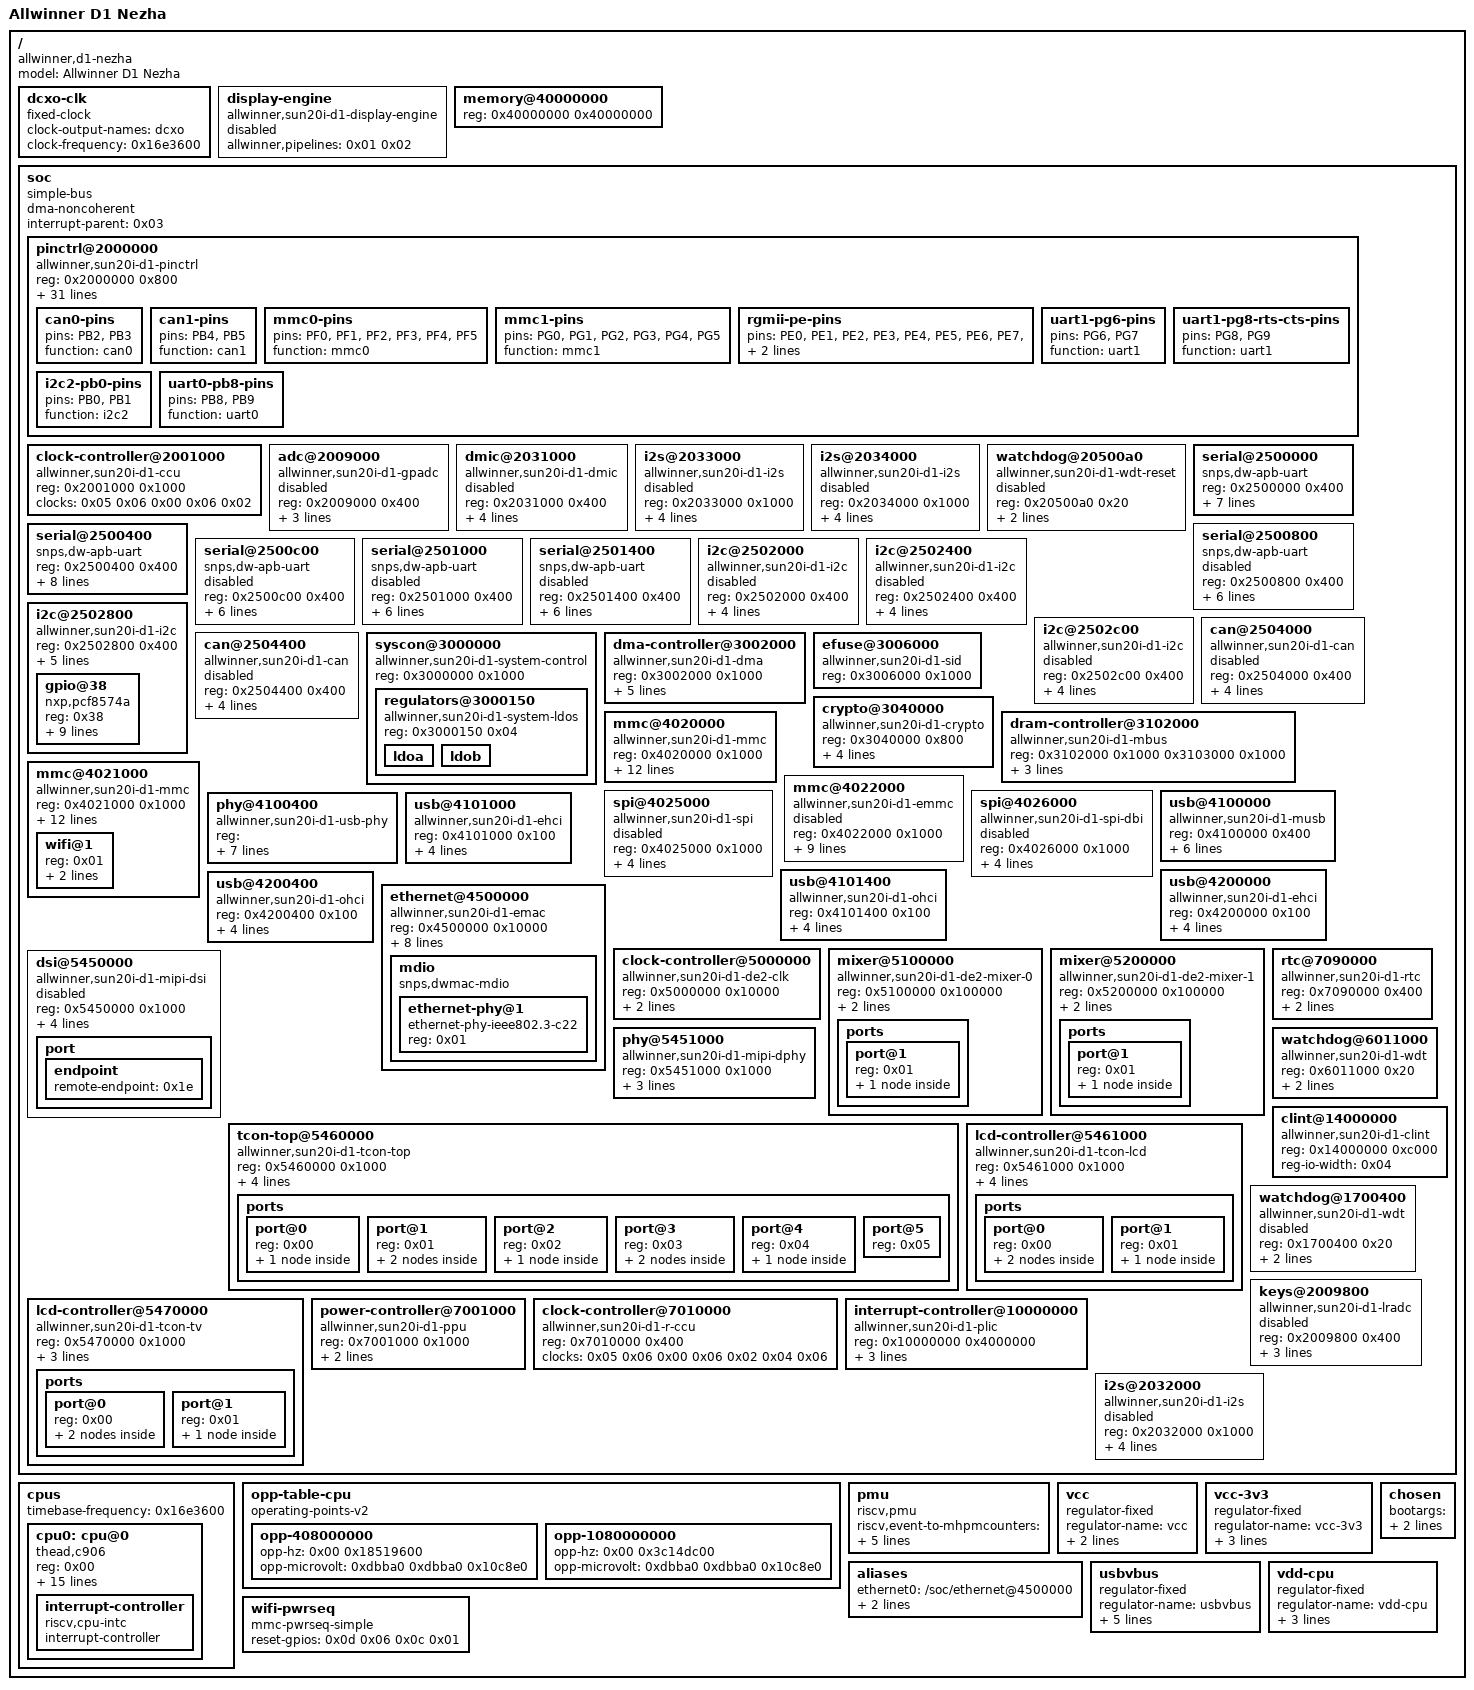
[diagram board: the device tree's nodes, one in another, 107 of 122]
/dts-v1/;

/ {
	#address-cells = <0x01>;
	#size-cells = <0x01>;
	model = "Allwinner D1 Nezha";
	compatible = "allwinner,d1-nezha", "allwinner,sun20i-d1";

	dcxo-clk {
		compatible = "fixed-clock";
		clock-output-names = "dcxo";
		#clock-cells = <0x00>;
		clock-frequency = <0x16e3600>;
		phandle = <0x05>;
	};

	display-engine {
		compatible = "allwinner,sun20i-d1-display-engine";
		allwinner,pipelines = <0x01 0x02>;
		status = "disabled";
	};

	memory@40000000 {
		device_type = "memory";
		reg = <0x40000000 0x40000000>;
	};

	soc {
		compatible = "simple-bus";
		ranges;
		dma-noncoherent;
		#address-cells = <0x01>;
		#size-cells = <0x01>;
		interrupt-parent = <0x03>;

		pinctrl@2000000 {
			compatible = "allwinner,sun20i-d1-pinctrl";
			reg = <0x2000000 0x800>;
			interrupts = <0x55 0x04 0x57 0x04 0x59 0x04 0x5b 0x04 0x5d 0x04 0x5f 0x04>;
			clocks = <0x04 0x18 0x05 0x06 0x00>;
			clock-names = "apb", "hosc", "losc";
			gpio-controller;
			interrupt-controller;
			#gpio-cells = <0x03>;
			#interrupt-cells = <0x03>;
			vcc-pb-supply = <0x07>;
			vcc-pc-supply = <0x07>;
			vcc-pd-supply = <0x07>;
			vcc-pe-supply = <0x07>;
			vcc-pf-supply = <0x07>;
			vcc-pg-supply = <0x07>;
			gpio-line-names = "", "", "", "", "", "", "", "", "", "", "", "", "", "", "", "", "", "", "", "", "", "", "", "", "", "", "", "", "", "", "", "", "pin5 [gpio2/twi2-sck]", "pin3 [gpio1/twi2-sda]", "", "pin38 [gpio24/i2s2-din]", "pin40 [gpio25/i2s2-dout]", "pin12 [gpio7/i2s-clk]", "pin35 [gpio22/i2s2-lrck]", "", "pin8 [gpio4/uart0-txd]", "pin10 [gpio5/uart0-rxd]", "", "", "pin15 [gpio9]", "", "", "", "", "", "", "", "", "", "", "", "", "", "", "", "", "", "", "", "", "", "pin31 [gpio21]", "", "", "", "", "", "", "", "", "", "", "", "", "", "", "", "", "", "", "", "", "", "", "", "", "", "", "", "", "", "", "", "", "", "", "", "", "", "", "", "", "pin24 [gpio16/spi1-ce0]", "pin23 [gpio15/spi1-clk]", "pin19 [gpio12/spi1-mosi]", "pin21 [gpio13/spi1-miso]", "pin27 [gpio18/spi1-hold]", "pin29 [gpio20/spi1-wp]", "", "", "", "", "", "", "pin7 [gpio3/pwm]";
			phandle = <0x0d>;

			can0-pins {
				pins = "PB2", "PB3";
				function = "can0";
				phandle = <0x0e>;
			};

			can1-pins {
				pins = "PB4", "PB5";
				function = "can1";
				phandle = <0x0f>;
			};

			mmc0-pins {
				pins = "PF0", "PF1", "PF2", "PF3", "PF4", "PF5";
				function = "mmc0";
				phandle = <0x10>;
			};

			mmc1-pins {
				pins = "PG0", "PG1", "PG2", "PG3", "PG4", "PG5";
				function = "mmc1";
				phandle = <0x12>;
			};

			rgmii-pe-pins {
				pins = "PE0", "PE1", "PE2", "PE3", "PE4", "PE5", "PE6", "PE7", "PE8", "PE9", "PE11", "PE12", "PE13", "PE14", "PE15";
				function = "emac";
				phandle = <0x17>;
			};

			uart1-pg6-pins {
				pins = "PG6", "PG7";
				function = "uart1";
				phandle = <0x0a>;
			};

			uart1-pg8-rts-cts-pins {
				pins = "PG8", "PG9";
				function = "uart1";
				phandle = <0x0b>;
			};

			i2c2-pb0-pins {
				pins = "PB0", "PB1";
				function = "i2c2";
				phandle = <0x0c>;
			};

			uart0-pb8-pins {
				pins = "PB8", "PB9";
				function = "uart0";
				phandle = <0x09>;
			};
		};

		clock-controller@2001000 {
			compatible = "allwinner,sun20i-d1-ccu";
			reg = <0x2001000 0x1000>;
			clocks = <0x05 0x06 0x00 0x06 0x02>;
			clock-names = "hosc", "losc", "iosc";
			#clock-cells = <0x01>;
			#reset-cells = <0x01>;
			phandle = <0x04>;
		};

		adc@2009000 {
			compatible = "allwinner,sun20i-d1-gpadc";
			reg = <0x2009000 0x400>;
			clocks = <0x04 0x50>;
			resets = <0x04 0x20>;
			interrupts = <0x49 0x04>;
			status = "disabled";
			#io-channel-cells = <0x01>;
		};

		dmic@2031000 {
			compatible = "allwinner,sun20i-d1-dmic", "allwinner,sun50i-h6-dmic";
			reg = <0x2031000 0x400>;
			interrupts = <0x28 0x04>;
			clocks = <0x04 0x5d 0x04 0x5c>;
			clock-names = "bus", "mod";
			resets = <0x04 0x26>;
			dmas = <0x08 0x08>;
			dma-names = "rx";
			status = "disabled";
			#sound-dai-cells = <0x00>;
		};

		i2s@2033000 {
			compatible = "allwinner,sun20i-d1-i2s", "allwinner,sun50i-r329-i2s";
			reg = <0x2033000 0x1000>;
			interrupts = <0x2b 0x04>;
			clocks = <0x04 0x57 0x04 0x53>;
			clock-names = "apb", "mod";
			resets = <0x04 0x23>;
			dmas = <0x08 0x04 0x08 0x04>;
			dma-names = "rx", "tx";
			status = "disabled";
			#sound-dai-cells = <0x00>;
		};

		i2s@2034000 {
			compatible = "allwinner,sun20i-d1-i2s", "allwinner,sun50i-r329-i2s";
			reg = <0x2034000 0x1000>;
			interrupts = <0x2c 0x04>;
			clocks = <0x04 0x58 0x04 0x54>;
			clock-names = "apb", "mod";
			resets = <0x04 0x24>;
			dmas = <0x08 0x05 0x08 0x05>;
			dma-names = "rx", "tx";
			status = "disabled";
			#sound-dai-cells = <0x00>;
		};

		// timer@2050000 {
		// 	compatible = "allwinner,sun20i-d1-timer", "allwinner,sun8i-a23-timer";
		// 	reg = <0x2050000 0xa0>;
		// 	interrupts = <0x4b 0x04 0x4c 0x04>;
		// 	clocks = <0x05>;
		// };

		watchdog@20500a0 {
			compatible = "allwinner,sun20i-d1-wdt-reset", "allwinner,sun20i-d1-wdt";
			reg = <0x20500a0 0x20>;
			interrupts = <0x4f 0x04>;
			clocks = <0x05 0x06 0x00>;
			clock-names = "hosc", "losc";
			status = "reserved";
		};

		serial@2500000 {
			compatible = "snps,dw-apb-uart";
			reg = <0x2500000 0x400>;
			reg-io-width = <0x04>;
			reg-shift = <0x02>;
			interrupts = <0x12 0x04>;
			clocks = <0x04 0x3e>;
			resets = <0x04 0x12>;
			dmas = <0x08 0x0e 0x08 0x0e>;
			dma-names = "tx", "rx";
			status = "okay";
			pinctrl-0 = <0x09>;
			pinctrl-names = "default";
		};

		serial@2500400 {
			compatible = "snps,dw-apb-uart";
			reg = <0x2500400 0x400>;
			reg-io-width = <0x04>;
			reg-shift = <0x02>;
			interrupts = <0x13 0x04>;
			clocks = <0x04 0x3f>;
			resets = <0x04 0x13>;
			dmas = <0x08 0x0f 0x08 0x0f>;
			dma-names = "tx", "rx";
			status = "okay";
			uart-has-rtscts;
			pinctrl-0 = <0x0a 0x0b>;
			pinctrl-names = "default";
		};

		serial@2500800 {
			compatible = "snps,dw-apb-uart";
			reg = <0x2500800 0x400>;
			reg-io-width = <0x04>;
			reg-shift = <0x02>;
			interrupts = <0x14 0x04>;
			clocks = <0x04 0x40>;
			resets = <0x04 0x14>;
			dmas = <0x08 0x10 0x08 0x10>;
			dma-names = "tx", "rx";
			status = "disabled";
		};

		serial@2500c00 {
			compatible = "snps,dw-apb-uart";
			reg = <0x2500c00 0x400>;
			reg-io-width = <0x04>;
			reg-shift = <0x02>;
			interrupts = <0x15 0x04>;
			clocks = <0x04 0x41>;
			resets = <0x04 0x15>;
			dmas = <0x08 0x11 0x08 0x11>;
			dma-names = "tx", "rx";
			status = "disabled";
		};

		serial@2501000 {
			compatible = "snps,dw-apb-uart";
			reg = <0x2501000 0x400>;
			reg-io-width = <0x04>;
			reg-shift = <0x02>;
			interrupts = <0x16 0x04>;
			clocks = <0x04 0x42>;
			resets = <0x04 0x16>;
			dmas = <0x08 0x12 0x08 0x12>;
			dma-names = "tx", "rx";
			status = "disabled";
		};

		serial@2501400 {
			compatible = "snps,dw-apb-uart";
			reg = <0x2501400 0x400>;
			reg-io-width = <0x04>;
			reg-shift = <0x02>;
			interrupts = <0x17 0x04>;
			clocks = <0x04 0x43>;
			resets = <0x04 0x17>;
			dmas = <0x08 0x13 0x08 0x13>;
			dma-names = "tx", "rx";
			status = "disabled";
		};

		i2c@2502000 {
			compatible = "allwinner,sun20i-d1-i2c", "allwinner,sun8i-v536-i2c", "allwinner,sun6i-a31-i2c";
			reg = <0x2502000 0x400>;
			interrupts = <0x19 0x04>;
			clocks = <0x04 0x44>;
			resets = <0x04 0x18>;
			dmas = <0x08 0x2b 0x08 0x2b>;
			dma-names = "rx", "tx";
			status = "disabled";
			#address-cells = <0x01>;
			#size-cells = <0x00>;
		};

		i2c@2502400 {
			compatible = "allwinner,sun20i-d1-i2c", "allwinner,sun8i-v536-i2c", "allwinner,sun6i-a31-i2c";
			reg = <0x2502400 0x400>;
			interrupts = <0x1a 0x04>;
			clocks = <0x04 0x45>;
			resets = <0x04 0x19>;
			dmas = <0x08 0x2c 0x08 0x2c>;
			dma-names = "rx", "tx";
			status = "disabled";
			#address-cells = <0x01>;
			#size-cells = <0x00>;
		};

		i2c@2502800 {
			compatible = "allwinner,sun20i-d1-i2c", "allwinner,sun8i-v536-i2c", "allwinner,sun6i-a31-i2c";
			reg = <0x2502800 0x400>;
			interrupts = <0x1b 0x04>;
			clocks = <0x04 0x46>;
			resets = <0x04 0x1a>;
			dmas = <0x08 0x2d 0x08 0x2d>;
			dma-names = "rx", "tx";
			status = "okay";
			#address-cells = <0x01>;
			#size-cells = <0x00>;
			pinctrl-0 = <0x0c>;
			pinctrl-names = "default";

			gpio@38 {
				compatible = "nxp,pcf8574a";
				reg = <0x38>;
				interrupt-parent = <0x0d>;
				interrupts = <0x01 0x02 0x08>;
				interrupt-controller;
				gpio-controller;
				#gpio-cells = <0x02>;
				#interrupt-cells = <0x02>;
				gpio-line-names = "pin13 [gpio8]", "pin16 [gpio10]", "pin18 [gpio11]", "pin26 [gpio17]", "pin22 [gpio14]", "pin28 [gpio19]", "pin37 [gpio23]", "pin11 [gpio6]";
			};
		};

		i2c@2502c00 {
			compatible = "allwinner,sun20i-d1-i2c", "allwinner,sun8i-v536-i2c", "allwinner,sun6i-a31-i2c";
			reg = <0x2502c00 0x400>;
			interrupts = <0x1c 0x04>;
			clocks = <0x04 0x47>;
			resets = <0x04 0x1b>;
			dmas = <0x08 0x2e 0x08 0x2e>;
			dma-names = "rx", "tx";
			status = "disabled";
			#address-cells = <0x01>;
			#size-cells = <0x00>;
		};

		can@2504000 {
			compatible = "allwinner,sun20i-d1-can";
			reg = <0x2504000 0x400>;
			interrupts = <0x25 0x04>;
			clocks = <0x04 0x91>;
			resets = <0x04 0x42>;
			pinctrl-names = "default";
			pinctrl-0 = <0x0e>;
			status = "disabled";
		};

		can@2504400 {
			compatible = "allwinner,sun20i-d1-can";
			reg = <0x2504400 0x400>;
			interrupts = <0x26 0x04>;
			clocks = <0x04 0x92>;
			resets = <0x04 0x43>;
			pinctrl-names = "default";
			pinctrl-0 = <0x0f>;
			status = "disabled";
		};

		syscon@3000000 {
			compatible = "allwinner,sun20i-d1-system-control";
			reg = <0x3000000 0x1000>;
			ranges;
			#address-cells = <0x01>;
			#size-cells = <0x01>;
			phandle = <0x16>;

			regulators@3000150 {
				compatible = "allwinner,sun20i-d1-system-ldos";
				reg = <0x3000150 0x04>;

				ldoa {
				};

				ldob {
				};
			};
		};

		dma-controller@3002000 {
			compatible = "allwinner,sun20i-d1-dma";
			reg = <0x3002000 0x1000>;
			interrupts = <0x42 0x04>;
			clocks = <0x04 0x25 0x04 0x30>;
			clock-names = "bus", "mbus";
			resets = <0x04 0x06>;
			dma-channels = <0x10>;
			dma-requests = <0x30>;
			#dma-cells = <0x01>;
			phandle = <0x08>;
		};

		efuse@3006000 {
			compatible = "allwinner,sun20i-d1-sid";
			reg = <0x3006000 0x1000>;
			#address-cells = <0x01>;
			#size-cells = <0x01>;
		};

		crypto@3040000 {
			compatible = "allwinner,sun20i-d1-crypto";
			reg = <0x3040000 0x800>;
			interrupts = <0x44 0x04>;
			clocks = <0x04 0x22 0x04 0x21 0x04 0x32 0x06 0x02>;
			clock-names = "bus", "mod", "ram", "trng";
			resets = <0x04 0x04>;
		};

		dram-controller@3102000 {
			compatible = "allwinner,sun20i-d1-mbus";
			reg = <0x3102000 0x1000 0x3103000 0x1000>;
			reg-names = "mbus", "dram";
			interrupts = <0x3b 0x04>;
			clocks = <0x04 0x1a 0x04 0x2f 0x04 0x37>;
			clock-names = "mbus", "dram", "bus";
			dma-ranges = <0x00 0x40000000 0x80000000>;
			#address-cells = <0x01>;
			#size-cells = <0x01>;
			#interconnect-cells = <0x01>;
		};

		mmc@4020000 {
			compatible = "allwinner,sun20i-d1-mmc";
			reg = <0x4020000 0x1000>;
			interrupts = <0x38 0x04>;
			clocks = <0x04 0x3b 0x04 0x38>;
			clock-names = "ahb", "mmc";
			resets = <0x04 0x0f>;
			reset-names = "ahb";
			cap-sd-highspeed;
			max-frequency = <0x8f0d180>;
			no-mmc;
			status = "okay";
			#address-cells = <0x01>;
			#size-cells = <0x00>;
			bus-width = <0x04>;
			cd-gpios = <0x0d 0x05 0x06 0x00>;
			disable-wp;
			vmmc-supply = <0x07>;
			vqmmc-supply = <0x07>;
			pinctrl-0 = <0x10>;
			pinctrl-names = "default";
		};

		mmc@4021000 {
			compatible = "allwinner,sun20i-d1-mmc";
			reg = <0x4021000 0x1000>;
			interrupts = <0x39 0x04>;
			clocks = <0x04 0x3c 0x04 0x39>;
			clock-names = "ahb", "mmc";
			resets = <0x04 0x10>;
			reset-names = "ahb";
			cap-sd-highspeed;
			max-frequency = <0x8f0d180>;
			no-mmc;
			status = "okay";
			#address-cells = <0x01>;
			#size-cells = <0x00>;
			bus-width = <0x04>;
			mmc-pwrseq = <0x11>;
			non-removable;
			vmmc-supply = <0x07>;
			vqmmc-supply = <0x07>;
			pinctrl-0 = <0x12>;
			pinctrl-names = "default";

			wifi@1 {
				reg = <0x01>;
				interrupt-parent = <0x0d>;
				interrupts = <0x06 0x0a 0x08>;
				interrupt-names = "host-wake";
			};
		};

		mmc@4022000 {
			compatible = "allwinner,sun20i-d1-emmc", "allwinner,sun50i-a100-emmc";
			reg = <0x4022000 0x1000>;
			interrupts = <0x3a 0x04>;
			clocks = <0x04 0x3d 0x04 0x3a>;
			clock-names = "ahb", "mmc";
			resets = <0x04 0x11>;
			reset-names = "ahb";
			cap-mmc-highspeed;
			max-frequency = <0x8f0d180>;
			mmc-ddr-1_8v;
			mmc-ddr-3_3v;
			no-sd;
			no-sdio;
			status = "disabled";
			#address-cells = <0x01>;
			#size-cells = <0x00>;
		};

		spi@4025000 {
			compatible = "allwinner,sun20i-d1-spi", "allwinner,sun50i-r329-spi";
			reg = <0x4025000 0x1000>;
			interrupts = <0x1f 0x04>;
			clocks = <0x04 0x4a 0x04 0x48>;
			clock-names = "ahb", "mod";
			dmas = <0x08 0x16 0x08 0x16>;
			dma-names = "rx", "tx";
			resets = <0x04 0x1c>;
			status = "disabled";
			#address-cells = <0x01>;
			#size-cells = <0x00>;
		};

		spi@4026000 {
			compatible = "allwinner,sun20i-d1-spi-dbi", "allwinner,sun50i-r329-spi-dbi", "allwinner,sun50i-r329-spi";
			reg = <0x4026000 0x1000>;
			interrupts = <0x20 0x04>;
			clocks = <0x04 0x4b 0x04 0x49>;
			clock-names = "ahb", "mod";
			dmas = <0x08 0x17 0x08 0x17>;
			dma-names = "rx", "tx";
			resets = <0x04 0x1d>;
			status = "disabled";
			#address-cells = <0x01>;
			#size-cells = <0x00>;
		};

		usb@4100000 {
			compatible = "allwinner,sun20i-d1-musb", "allwinner,sun8i-a33-musb";
			reg = <0x4100000 0x400>;
			interrupts = <0x2d 0x04>;
			interrupt-names = "mc";
			clocks = <0x04 0x67>;
			resets = <0x04 0x2e>;
			extcon = <0x13 0x00>;
			phys = <0x13 0x00>;
			phy-names = "usb";
			status = "okay";
			dr_mode = "otg";
		};

		phy@4100400 {
			compatible = "allwinner,sun20i-d1-usb-phy";
			reg = <0x4100400 0x100 0x4101800 0x100 0x4200800 0x100>;
			reg-names = "phy_ctrl", "pmu0", "pmu1";
			clocks = <0x05 0x05>;
			clock-names = "usb0_phy", "usb1_phy";
			resets = <0x04 0x28 0x04 0x29>;
			reset-names = "usb0_reset", "usb1_reset";
			status = "okay";
			#phy-cells = <0x01>;
			usb0_id_det-gpios = <0x0d 0x03 0x15 0x00>;
			usb0_vbus_det-gpios = <0x0d 0x03 0x14 0x00>;
			usb0_vbus-supply = <0x14>;
			usb1_vbus-supply = <0x15>;
			phandle = <0x13>;
		};

		usb@4101000 {
			compatible = "allwinner,sun20i-d1-ehci", "generic-ehci";
			reg = <0x4101000 0x100>;
			interrupts = <0x2e 0x04>;
			clocks = <0x04 0x63 0x04 0x65 0x04 0x61>;
			resets = <0x04 0x2a 0x04 0x2c>;
			phys = <0x13 0x00>;
			phy-names = "usb";
			status = "okay";
		};

		usb@4101400 {
			compatible = "allwinner,sun20i-d1-ohci", "generic-ohci";
			reg = <0x4101400 0x100>;
			interrupts = <0x2f 0x04>;
			clocks = <0x04 0x63 0x04 0x61>;
			resets = <0x04 0x2a>;
			phys = <0x13 0x00>;
			phy-names = "usb";
			status = "okay";
		};

		usb@4200000 {
			compatible = "allwinner,sun20i-d1-ehci", "generic-ehci";
			reg = <0x4200000 0x100>;
			interrupts = <0x31 0x04>;
			clocks = <0x04 0x64 0x04 0x66 0x04 0x62>;
			resets = <0x04 0x2b 0x04 0x2d>;
			phys = <0x13 0x01>;
			phy-names = "usb";
			status = "okay";
		};

		usb@4200400 {
			compatible = "allwinner,sun20i-d1-ohci", "generic-ohci";
			reg = <0x4200400 0x100>;
			interrupts = <0x32 0x04>;
			clocks = <0x04 0x64 0x04 0x62>;
			resets = <0x04 0x2b>;
			phys = <0x13 0x01>;
			phy-names = "usb";
			status = "okay";
		};

		ethernet@4500000 {
			compatible = "allwinner,sun20i-d1-emac", "allwinner,sun50i-a64-emac";
			reg = <0x4500000 0x10000>;
			interrupts = <0x3e 0x04>;
			interrupt-names = "macirq";
			clocks = <0x04 0x4d>;
			clock-names = "stmmaceth";
			resets = <0x04 0x1e>;
			reset-names = "stmmaceth";
			syscon = <0x16>;
			status = "okay";
			pinctrl-0 = <0x17>;
			pinctrl-names = "default";
			phy-handle = <0x18>;
			phy-mode = "rgmii-id";
			phy-supply = <0x07>;

			mdio {
				compatible = "snps,dwmac-mdio";
				#address-cells = <0x01>;
				#size-cells = <0x00>;

				ethernet-phy@1 {
					compatible = "ethernet-phy-ieee802.3-c22";
					reg = <0x01>;
					phandle = <0x18>;
				};
			};
		};

		clock-controller@5000000 {
			compatible = "allwinner,sun20i-d1-de2-clk", "allwinner,sun50i-h5-de2-clk";
			reg = <0x5000000 0x10000>;
			clocks = <0x04 0x1c 0x04 0x1b>;
			clock-names = "bus", "mod";
			resets = <0x04 0x01>;
			#clock-cells = <0x01>;
			#reset-cells = <0x01>;
			phandle = <0x19>;
		};

		mixer@5100000 {
			compatible = "allwinner,sun20i-d1-de2-mixer-0";
			reg = <0x5100000 0x100000>;
			clocks = <0x19 0x00 0x19 0x06>;
			clock-names = "bus", "mod";
			resets = <0x19 0x00>;
			phandle = <0x01>;

			ports {
				#address-cells = <0x01>;
				#size-cells = <0x00>;

				port@1 {
					reg = <0x01>;

					endpoint {
						remote-endpoint = <0x1a>;
						phandle = <0x1f>;
					};
				};
			};
		};

		mixer@5200000 {
			compatible = "allwinner,sun20i-d1-de2-mixer-1";
			reg = <0x5200000 0x100000>;
			clocks = <0x19 0x01 0x19 0x07>;
			clock-names = "bus", "mod";
			resets = <0x19 0x01>;
			phandle = <0x02>;

			ports {
				#address-cells = <0x01>;
				#size-cells = <0x00>;

				port@1 {
					reg = <0x01>;

					endpoint {
						remote-endpoint = <0x1b>;
						phandle = <0x22>;
					};
				};
			};
		};

		dsi@5450000 {
			compatible = "allwinner,sun20i-d1-mipi-dsi", "allwinner,sun50i-a100-mipi-dsi";
			reg = <0x5450000 0x1000>;
			interrupts = <0x6c 0x04>;
			clocks = <0x04 0x6f 0x1c 0x02>;
			clock-names = "bus", "mod";
			resets = <0x04 0x33>;
			phys = <0x1d>;
			phy-names = "dphy";
			status = "disabled";

			port {

				endpoint {
					remote-endpoint = <0x1e>;
					phandle = <0x28>;
				};
			};
		};

		phy@5451000 {
			compatible = "allwinner,sun20i-d1-mipi-dphy", "allwinner,sun50i-a100-mipi-dphy";
			reg = <0x5451000 0x1000>;
			interrupts = <0x6c 0x04>;
			clocks = <0x04 0x6f 0x04 0x6e>;
			clock-names = "bus", "mod";
			resets = <0x04 0x33>;
			#phy-cells = <0x00>;
			phandle = <0x1d>;
		};

		tcon-top@5460000 {
			compatible = "allwinner,sun20i-d1-tcon-top";
			reg = <0x5460000 0x1000>;
			clocks = <0x04 0x69 0x04 0x72 0x04 0x74 0x04 0x70>;
			clock-names = "bus", "tcon-tv0", "tve0", "dsi";
			clock-output-names = "tcon-top-tv0", "tcon-top-dsi";
			resets = <0x04 0x30>;
			#clock-cells = <0x01>;
			phandle = <0x1c>;

			ports {
				#address-cells = <0x01>;
				#size-cells = <0x00>;

				port@0 {
					reg = <0x00>;

					endpoint {
						remote-endpoint = <0x1f>;
						phandle = <0x1a>;
					};
				};

				port@1 {
					reg = <0x01>;
					#address-cells = <0x01>;
					#size-cells = <0x00>;

					endpoint@0 {
						reg = <0x00>;
						remote-endpoint = <0x20>;
						phandle = <0x26>;
					};

					endpoint@2 {
						reg = <0x02>;
						remote-endpoint = <0x21>;
						phandle = <0x29>;
					};
				};

				port@2 {
					reg = <0x02>;
					#address-cells = <0x01>;
					#size-cells = <0x00>;

					endpoint@1 {
						reg = <0x01>;
						remote-endpoint = <0x22>;
						phandle = <0x1b>;
					};
				};

				port@3 {
					reg = <0x03>;
					#address-cells = <0x01>;
					#size-cells = <0x00>;

					endpoint@0 {
						reg = <0x00>;
						remote-endpoint = <0x23>;
						phandle = <0x27>;
					};

					endpoint@2 {
						reg = <0x02>;
						remote-endpoint = <0x24>;
						phandle = <0x2a>;
					};
				};

				port@4 {
					reg = <0x04>;

					endpoint {
						remote-endpoint = <0x25>;
						phandle = <0x2b>;
					};
				};

				port@5 {
					reg = <0x05>;
				};
			};
		};

		lcd-controller@5461000 {
			compatible = "allwinner,sun20i-d1-tcon-lcd";
			reg = <0x5461000 0x1000>;
			interrupts = <0x6a 0x04>;
			clocks = <0x04 0x71 0x04 0x70>;
			clock-names = "ahb", "tcon-ch0";
			clock-output-names = "tcon-pixel-clock";
			resets = <0x04 0x34 0x04 0x36>;
			reset-names = "lcd", "lvds";
			#clock-cells = <0x00>;

			ports {
				#address-cells = <0x01>;
				#size-cells = <0x00>;

				port@0 {
					reg = <0x00>;
					#address-cells = <0x01>;
					#size-cells = <0x00>;

					endpoint@0 {
						reg = <0x00>;
						remote-endpoint = <0x26>;
						phandle = <0x20>;
					};

					endpoint@1 {
						reg = <0x01>;
						remote-endpoint = <0x27>;
						phandle = <0x23>;
					};
				};

				port@1 {
					reg = <0x01>;
					#address-cells = <0x01>;
					#size-cells = <0x00>;

					endpoint@1 {
						reg = <0x01>;
						remote-endpoint = <0x28>;
						phandle = <0x1e>;
					};
				};
			};
		};

		lcd-controller@5470000 {
			compatible = "allwinner,sun20i-d1-tcon-tv";
			reg = <0x5470000 0x1000>;
			interrupts = <0x6b 0x04>;
			clocks = <0x04 0x73 0x1c 0x00>;
			clock-names = "ahb", "tcon-ch1";
			resets = <0x04 0x35>;
			reset-names = "lcd";

			ports {
				#address-cells = <0x01>;
				#size-cells = <0x00>;

				port@0 {
					reg = <0x00>;
					#address-cells = <0x01>;
					#size-cells = <0x00>;

					endpoint@0 {
						reg = <0x00>;
						remote-endpoint = <0x29>;
						phandle = <0x21>;
					};

					endpoint@1 {
						reg = <0x01>;
						remote-endpoint = <0x2a>;
						phandle = <0x24>;
					};
				};

				port@1 {
					reg = <0x01>;

					endpoint {
						remote-endpoint = <0x2b>;
						phandle = <0x25>;
					};
				};
			};
		};

		power-controller@7001000 {
			compatible = "allwinner,sun20i-d1-ppu";
			reg = <0x7001000 0x1000>;
			clocks = <0x2c 0x04>;
			resets = <0x2c 0x02>;
			#power-domain-cells = <0x01>;
		};

		clock-controller@7010000 {
			compatible = "allwinner,sun20i-d1-r-ccu";
			reg = <0x7010000 0x400>;
			clocks = <0x05 0x06 0x00 0x06 0x02 0x04 0x06>;
			clock-names = "hosc", "losc", "iosc", "pll-periph";
			#clock-cells = <0x01>;
			#reset-cells = <0x01>;
			phandle = <0x2c>;
		};

		rtc@7090000 {
			compatible = "allwinner,sun20i-d1-rtc", "allwinner,sun50i-r329-rtc";
			reg = <0x7090000 0x400>;
			interrupts = <0xa0 0x04>;
			clocks = <0x2c 0x07 0x05 0x2c 0x00>;
			clock-names = "bus", "hosc", "ahb";
			#clock-cells = <0x01>;
			phandle = <0x06>;
		};

		watchdog@6011000 {
			compatible = "allwinner,sun20i-d1-wdt";
			reg = <0x6011000 0x20>;
			interrupts = <0x93 0x04>;
			clocks = <0x05 0x06 0x00>;
			clock-names = "hosc", "losc";
		};

		interrupt-controller@10000000 {
			compatible = "allwinner,sun20i-d1-plic", "thead,c900-plic";
			reg = <0x10000000 0x4000000>;
			interrupts-extended = <0x2d 0x0b 0x2d 0x09>;
			interrupt-controller;
			riscv,ndev = <0xaf>;
			#address-cells = <0x00>;
			#interrupt-cells = <0x02>;
			phandle = <0x03>;
		};

		clint@14000000 {
			compatible = "allwinner,sun20i-d1-clint", "sifive,clint0";
			reg = <0x14000000 0xc000>;
			reg-io-width = <0x04>;
		};

		watchdog@1700400 {
			compatible = "allwinner,sun20i-d1-wdt";
			reg = <0x1700400 0x20>;
			interrupts = <0x8a 0x04>;
			clocks = <0x05 0x06 0x00>;
			clock-names = "hosc", "losc";
			status = "reserved";
		};

		keys@2009800 {
			compatible = "allwinner,sun20i-d1-lradc", "allwinner,sun50i-r329-lradc";
			reg = <0x2009800 0x400>;
			interrupts = <0x4d 0x04>;
			clocks = <0x04 0x68>;
			resets = <0x04 0x2f>;
			status = "disabled";
		};

		i2s@2032000 {
			compatible = "allwinner,sun20i-d1-i2s", "allwinner,sun50i-r329-i2s";
			reg = <0x2032000 0x1000>;
			interrupts = <0x2a 0x04>;
			clocks = <0x04 0x56 0x04 0x52>;
			clock-names = "apb", "mod";
			resets = <0x04 0x22>;
			dmas = <0x08 0x03 0x08 0x03>;
			dma-names = "rx", "tx";
			status = "disabled";
			#sound-dai-cells = <0x00>;
		};
	};

	cpus {
		timebase-frequency = <0x16e3600>;
		#address-cells = <0x01>;
		#size-cells = <0x00>;

		cpu0: cpu@0 {
			compatible = "thead,c906", "riscv";
			device_type = "cpu";
			reg = <0x00>;
			clocks = <0x04 0x84>;
			d-cache-block-size = <0x40>;
			d-cache-sets = <0x100>;
			d-cache-size = <0x8000>;
			i-cache-block-size = <0x40>;
			i-cache-sets = <0x80>;
			i-cache-size = <0x8000>;
			mmu-type = "riscv,sv39";
			operating-points-v2 = <0x2e>;
			riscv,isa = "rv64imafdc";
			riscv,isa-base = "rv64i";
			riscv,isa-extensions = "i", "m", "a", "f", "d", "c", "zicntr", "zicsr", "zifencei", "zihpm", "xtheadvector";
			thead,vlenb = <0x80>;
			#cooling-cells = <0x02>;
			cpu-supply = <0x2f>;

			interrupt-controller {
				compatible = "riscv,cpu-intc";
				interrupt-controller;
				#interrupt-cells = <0x01>;
				phandle = <0x2d>;
			};
		};
	};

	opp-table-cpu {
		compatible = "operating-points-v2";
		phandle = <0x2e>;

		opp-408000000 {
			opp-hz = <0x00 0x18519600>;
			opp-microvolt = <0xdbba0 0xdbba0 0x10c8e0>;
		};

		opp-1080000000 {
			opp-hz = <0x00 0x3c14dc00>;
			opp-microvolt = <0xdbba0 0xdbba0 0x10c8e0>;
		};
	};

	pmu {
		compatible = "riscv,pmu";
		riscv,event-to-mhpmcounters = <0x03 0x03 0x08 0x04 0x04 0x10 0x05 0x05 0x200 0x06 0x06 0x100 0x10000 0x10000 0x4000 0x10001 0x10001 0x8000 0x10002 0x10002 0x10000 0x10003 0x10003 0x20000 0x10019 0x10019 0x40 0x10021 0x10021 0x20>;
		riscv,event-to-mhpmevent = <0x03 0x00 0x01 0x04 0x00 0x02 0x05 0x00 0x07 0x06 0x00 0x06 0x10000 0x00 0x0c 0x10001 0x00 0x0d 0x10002 0x00 0x0e 0x10003 0x00 0x0f 0x10019 0x00 0x04 0x10021 0x00 0x03>;
		riscv,raw-event-to-mhpmcounters = <0x00 0x01 0xffffffff 0xffffffff 0x08 0x00 0x02 0xffffffff 0xffffffff 0x10 0x00 0x03 0xffffffff 0xffffffff 0x20 0x00 0x04 0xffffffff 0xffffffff 0x40 0x00 0x05 0xffffffff 0xffffffff 0x80 0x00 0x06 0xffffffff 0xffffffff 0x100 0x00 0x07 0xffffffff 0xffffffff 0x200 0x00 0x0b 0xffffffff 0xffffffff 0x2000 0x00 0x0c 0xffffffff 0xffffffff 0x4000 0x00 0x0d 0xffffffff 0xffffffff 0x8000 0x00 0x0e 0xffffffff 0xffffffff 0x10000 0x00 0x0f 0xffffffff 0xffffffff 0x20000>;
	};

	vcc {
		compatible = "regulator-fixed";
		regulator-name = "vcc";
		regulator-min-microvolt = <0x4c4b40>;
		regulator-max-microvolt = <0x4c4b40>;
		phandle = <0x15>;
	};

	vcc-3v3 {
		compatible = "regulator-fixed";
		regulator-name = "vcc-3v3";
		regulator-min-microvolt = <0x325aa0>;
		regulator-max-microvolt = <0x325aa0>;
		vin-supply = <0x15>;
		phandle = <0x07>;
	};

	aliases {
		ethernet0 = "/soc/ethernet@4500000";
		ethernet1 = "/soc/mmc@4021000/wifi@1";
		serial0 = "/soc/serial@2500000";
	};

	chosen {
		bootargs = "console=ttyS0,115200n8 debug loglevel=7,initcall_debug=1 earlycon=sbi clk_ignore_unused initcall_debug=0 console=ttyS0,115200 root=/dev/mmcblk0p2 rw cma=8M mac_addr=84:10:12:12:01:04 LANG=en_US.UTF-8";
		stdout-path = "serial0:115200n8";
	};

	usbvbus {
		compatible = "regulator-fixed";
		regulator-name = "usbvbus";
		regulator-min-microvolt = <0x4c4b40>;
		regulator-max-microvolt = <0x4c4b40>;
		gpio = <0x0d 0x03 0x13 0x00>;
		enable-active-high;
		vin-supply = <0x15>;
		phandle = <0x14>;
	};

	vdd-cpu {
		compatible = "regulator-fixed";
		regulator-name = "vdd-cpu";
		regulator-min-microvolt = <0x10c8e0>;
		regulator-max-microvolt = <0x10c8e0>;
		vin-supply = <0x15>;
		phandle = <0x2f>;
	};

	wifi-pwrseq {
		compatible = "mmc-pwrseq-simple";
		reset-gpios = <0x0d 0x06 0x0c 0x01>;
		phandle = <0x11>;
	};
};
